# MSS_CPSW register map
Vendor: Texas Instruments
Registers are 32-bit, read-write, no defined reset value unless marked. A register's access mark holds for its fields unless they carry their own. Offsets are as the file gives them; [hi:lo] are bit positions; {n}, {i} and the like mark numbered series.

## MSS_CPSW (part 3 of 3)
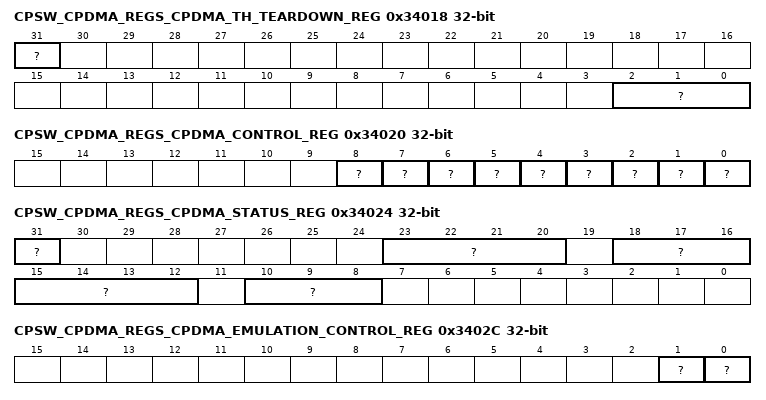
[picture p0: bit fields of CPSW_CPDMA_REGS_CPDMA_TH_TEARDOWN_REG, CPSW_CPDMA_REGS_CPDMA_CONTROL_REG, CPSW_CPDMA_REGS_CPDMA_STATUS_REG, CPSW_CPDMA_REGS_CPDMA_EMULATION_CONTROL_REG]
0x34018 CPSW_CPDMA_REGS_CPDMA_TH_TEARDOWN_REG — CPDMA THost Teardown Register
  [31] ? — CPDMA THost Teardown Ready
  [2:0] ? — CPDMA THost Teardown Channel
0x3401C CPSW_CPDMA_REGS_CPDMA_SOFT_RESET_REG — CPDMA Soft Reset Register
  [0] ? — CPDMA and CPSW Soft Reset Enable
0x34020 CPSW_CPDMA_REGS_CPDMA_CONTROL_REG — CPDMA Control Register
  [8] ? — CPDMA FHost Ownership Write Bit Value
  [7] ? — CPDMA Channel Thread Override Enable
  [6] ? — CPDMA THost TimeStamp Encapsulated
  [5] ? — CPDMA THost VLAN Encapsulated
  [4] ? — CPDMA THost Copy Error Frames
  [3] ? — CPDMA Command Idle
  [2] ? — CPDMA THost Offset/Length Word Write Block
  [1] ? — CPDMA THost Ownership Write Bit Value
  [0] ? — CPDMA FHost Queue Priority Type
0x34024 CPSW_CPDMA_REGS_CPDMA_STATUS_REG ro — CPDMA Status Register
  [31] ? — CPDMA FHost Host Error Code
  [23:20] ? — CPDMA FHost Host Error Code
  [18:16] ? — CPDMA FHost Error Channel Number
  [15:12] ? — CPDMA THost Host Error Code
  [10:8] ? — CPDMA THost Error Channel Number
0x34028 CPSW_CPDMA_REGS_CPDMA_TH_BUFFER_OFFSET_REG — CPDMA THost Buffer Offset Register
  [11:0] ?
0x3402C CPSW_CPDMA_REGS_CPDMA_EMULATION_CONTROL_REG — CPDMA THost Buffer Offset Register
  [1] ? — CPDMA THost Buffer Offset Register
  [0] ? — CPDMA THost Buffer Offset Register
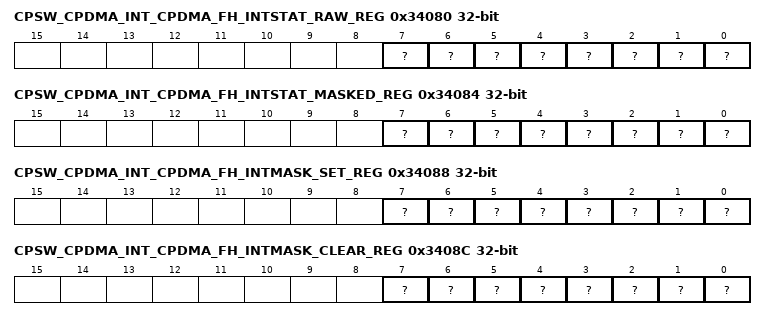
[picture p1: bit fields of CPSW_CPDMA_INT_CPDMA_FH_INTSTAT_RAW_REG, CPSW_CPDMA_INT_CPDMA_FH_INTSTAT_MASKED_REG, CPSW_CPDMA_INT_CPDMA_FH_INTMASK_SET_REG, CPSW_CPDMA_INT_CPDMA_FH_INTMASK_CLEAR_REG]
0x34080 CPSW_CPDMA_INT_CPDMA_FH_INTSTAT_RAW_REG ro — CPDMA FHost Interrupt Status RAW
  [7] ? — CPDMA FHost Channel 7 Interrupt Pending RAW
  [6] ? — CPDMA FHost Channel 6 Interrupt Pending RAW
  [5] ? — CPDMA FHost Channel 5 Interrupt Pending RAW
  [4] ? — CPDMA FHost Channel 4 Interrupt Pending RAW
  [3] ? — CPDMA FHost Channel 3 Interrupt Pending RAW
  [2] ? — CPDMA FHost Channel 2 Interrupt Pending RAW
  [1] ? — CPDMA FHost Channel 1 Interrupt Pending RAW
  [0] ? — CPDMA FHost Channel 0 Interrupt Pending RAW
0x34084 CPSW_CPDMA_INT_CPDMA_FH_INTSTAT_MASKED_REG ro — CPDMA FHost Interrupt Status MASKED
  [7] ? — CPDMA FHost Channel 7 Interrupt Pending MASKED
  [6] ? — CPDMA FHost Channel 6 Interrupt Pending MASKED
  [5] ? — CPDMA FHost Channel 5 Interrupt Pending MASKED
  [4] ? — CPDMA FHost Channel 4 Interrupt Pending MASKED
  [3] ? — CPDMA FHost Channel 3 Interrupt Pending MASKED
  [2] ? — CPDMA FHost Channel 2 Interrupt Pending MASKED
  [1] ? — CPDMA FHost Channel 1 Interrupt Pending MASKED
  [0] ? — CPDMA FHost Channel 0 Interrupt Pending MASKED
0x34088 CPSW_CPDMA_INT_CPDMA_FH_INTMASK_SET_REG — CPDMA FHost Interrupt Masked SET
  [7] ? — CPDMA FHost Channel 7 Interrupt Pending MASKED Set
  [6] ? — CPDMA FHost Channel 6 Interrupt Pending MASKED Set
  [5] ? — CPDMA FHost Channel 5 Interrupt Pending MASKED Set
  [4] ? — CPDMA FHost Channel 4 Interrupt Pending MASKED Set
  [3] ? — CPDMA FHost Channel 3 Interrupt Pending MASKED Set
  [2] ? — CPDMA FHost Channel 2 Interrupt Pending MASKED Set
  [1] ? — CPDMA FHost Channel 1 Interrupt Pending MASKED Set
  [0] ? — CPDMA FHost Channel 0 Interrupt Pending MASKED Set
0x3408C CPSW_CPDMA_INT_CPDMA_FH_INTMASK_CLEAR_REG — CPDMA FHost Interrupt Masked CLR
  [7] ? — CPDMA FHost Channel 7 Interrupt Pending MASKED Clr
  [6] ? — CPDMA FHost Channel 6 Interrupt Pending MASKED Clr
  [5] ? — CPDMA FHost Channel 5 Interrupt Pending MASKED Clr
  [4] ? — CPDMA FHost Channel 4 Interrupt Pending MASKED Clr
  [3] ? — CPDMA FHost Channel 3 Interrupt Pending MASKED Clr
  [2] ? — CPDMA FHost Channel 2 Interrupt Pending MASKED Clr
  [1] ? — CPDMA FHost Channel 1 Interrupt Pending MASKED Clr
  [0] ? — CPDMA FHost Channel 0 Interrupt Pending MASKED Clr
0x34090 CPSW_CPDMA_INT_CPDMA_IN_VECTOR_REG ro — CPDMA DMA IN Vector
  [31:0] ?
0x34094 CPSW_CPDMA_INT_CPDMA_EOI_VECTOR_REG — CPDMA DMA EOI Vector
  [4:0] ?
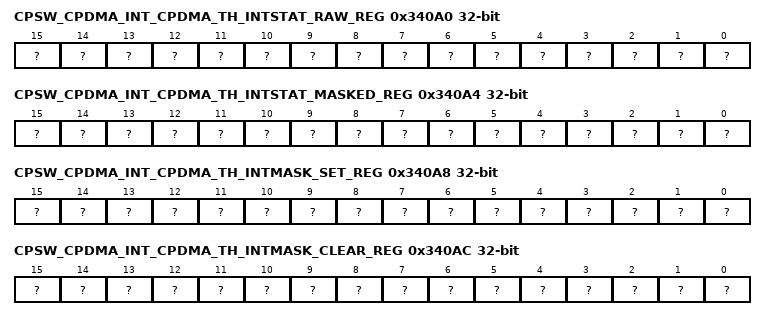
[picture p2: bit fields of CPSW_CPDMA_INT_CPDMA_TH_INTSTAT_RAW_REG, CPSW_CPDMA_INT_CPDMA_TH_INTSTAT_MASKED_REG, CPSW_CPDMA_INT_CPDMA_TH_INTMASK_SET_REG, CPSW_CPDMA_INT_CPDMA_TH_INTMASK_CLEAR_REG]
0x340A0 CPSW_CPDMA_INT_CPDMA_TH_INTSTAT_RAW_REG ro — CPDMA Receive Interrupt Status RAW
  [15] ? — CPDMA Receive Channel 7 Threshold Interrupt Pending RAW
  [14] ? — CPDMA Receive Channel 6 Threshold Interrupt Pending RAW
  [13] ? — CPDMA Receive Channel 5 Threshold Interrupt Pending RAW
  [12] ? — CPDMA Receive Channel 4 Threshold Interrupt Pending RAW
  [11] ? — CPDMA Receive Channel 3 Threshold Interrupt Pending RAW
  [10] ? — CPDMA Receive Channel 2 Threshold Interrupt Pending RAW
  [9] ? — CPDMA Receive Channel 1 Threshold Interrupt Pending RAW
  [8] ? — CPDMA Receive Channel 0 Threshold Interrupt Pending RAW
  [7] ? — CPDMA Receive Channel 7 Interrupt Pending RAW
  [6] ? — CPDMA Receive Channel 6 Interrupt Pending RAW
  [5] ? — CPDMA Receive Channel 5 Interrupt Pending RAW
  [4] ? — CPDMA Receive Channel 4 Interrupt Pending RAW
  [3] ? — CPDMA Receive Channel 3 Interrupt Pending RAW
  [2] ? — CPDMA Receive Channel 2 Interrupt Pending RAW
  [1] ? — CPDMA Receive Channel 1 Interrupt Pending RAW
  [0] ? — CPDMA Receive Channel 0 Interrupt Pending RAW
0x340A4 CPSW_CPDMA_INT_CPDMA_TH_INTSTAT_MASKED_REG ro — CPDMA Receive Interrupt Status MASKED
  [15] ? — CPDMA Receive Channel 7 Threshold Interrupt Pending MASKED
  [14] ? — CPDMA Receive Channel 6 Threshold Interrupt Pending MASKED
  [13] ? — CPDMA Receive Channel 5 Threshold Interrupt Pending MASKED
  [12] ? — CPDMA Receive Channel 4 Threshold Interrupt Pending MASKED
  [11] ? — CPDMA Receive Channel 3 Threshold Interrupt Pending MASKED
  [10] ? — CPDMA Receive Channel 2 Threshold Interrupt Pending MASKED
  [9] ? — CPDMA Receive Channel 1 Threshold Interrupt Pending MASKED
  [8] ? — CPDMA Receive Channel 0 Threshold Interrupt Pending MASKED
  [7] ? — CPDMA Receive Channel 7 Interrupt Pending MASKED
  [6] ? — CPDMA Receive Channel 6 Interrupt Pending MASKED
  [5] ? — CPDMA Receive Channel 5 Interrupt Pending MASKED
  [4] ? — CPDMA Receive Channel 4 Interrupt Pending MASKED
  [3] ? — CPDMA Receive Channel 3 Interrupt Pending MASKED
  [2] ? — CPDMA Receive Channel 2 Interrupt Pending MASKED
  [1] ? — CPDMA Receive Channel 1 Interrupt Pending MASKED
  [0] ? — CPDMA Receive Channel 0 Interrupt Pending MASKED
0x340A8 CPSW_CPDMA_INT_CPDMA_TH_INTMASK_SET_REG — CPDMA THost Interrupt Masked SET
  [15] ? — CPDMA THost Channel 7 Threshold Interrupt Pending SET
  [14] ? — CPDMA THost Channel 6 Threshold Interrupt Pending SET
  [13] ? — CPDMA THost Channel 5 Threshold Interrupt Pending SET
  [12] ? — CPDMA THost Channel 4 Threshold Interrupt Pending SET
  [11] ? — CPDMA THost Channel 3 Threshold Interrupt Pending SET
  [10] ? — CPDMA THost Channel 2 Threshold Interrupt Pending SET
  [9] ? — CPDMA THost Channel 1 Threshold Interrupt Pending SET
  [8] ? — CPDMA THost Channel 0 Threshold Interrupt Pending SET
  [7] ? — CPDMA THost Channel 7 Interrupt Pending SET
  [6] ? — CPDMA THost Channel 6 Interrupt Pending SET
  [5] ? — CPDMA THost Channel 5 Interrupt Pending SET
  [4] ? — CPDMA THost Channel 4 Interrupt Pending SET
  [3] ? — CPDMA THost Channel 3 Interrupt Pending SET
  [2] ? — CPDMA THost Channel 2 Interrupt Pending SET
  [1] ? — CPDMA THost Channel 1 Interrupt Pending SET
  [0] ? — CPDMA THost Channel 0 Interrupt Pending SET
0x340AC CPSW_CPDMA_INT_CPDMA_TH_INTMASK_CLEAR_REG — CPDMA THost Interrupt Masked CLR
  [15] ? — CPDMA THost Channel 7 Threshold Interrupt Pending CLR
  [14] ? — CPDMA THost Channel 6 Threshold Interrupt Pending CLR
  [13] ? — CPDMA THost Channel 5 Threshold Interrupt Pending CLR
  [12] ? — CPDMA THost Channel 4 Threshold Interrupt Pending CLR
  [11] ? — CPDMA THost Channel 3 Threshold Interrupt Pending CLR
  [10] ? — CPDMA THost Channel 2 Threshold Interrupt Pending CLR
  [9] ? — CPDMA THost Channel 1 Threshold Interrupt Pending CLR
  [8] ? — CPDMA THost Channel 0 Threshold Interrupt Pending CLR
  [7] ? — CPDMA THost Channel 7 Interrupt Pending CLR
  [6] ? — CPDMA THost Channel 6 Interrupt Pending CLR
  [5] ? — CPDMA THost Channel 5 Interrupt Pending CLR
  [4] ? — CPDMA THost Channel 4 Interrupt Pending CLR
  [3] ? — CPDMA THost Channel 3 Interrupt Pending CLR
  [2] ? — CPDMA THost Channel 2 Interrupt Pending CLR
  [1] ? — CPDMA THost Channel 1 Interrupt Pending CLR
  [0] ? — CPDMA THost Channel 0 Interrupt Pending CLR
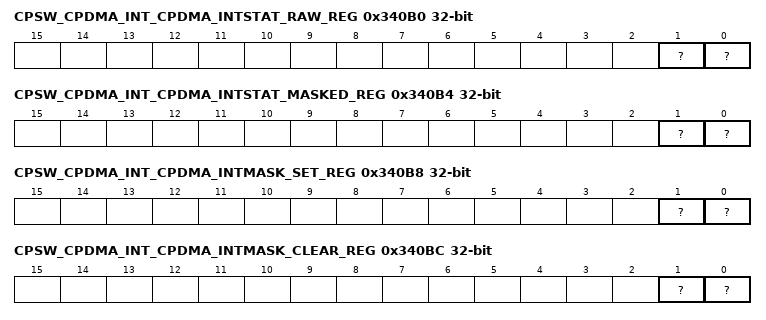
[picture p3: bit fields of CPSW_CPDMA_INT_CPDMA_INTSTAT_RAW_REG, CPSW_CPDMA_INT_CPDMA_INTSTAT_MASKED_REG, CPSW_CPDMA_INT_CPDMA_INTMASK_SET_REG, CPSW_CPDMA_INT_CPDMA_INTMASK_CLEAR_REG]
0x340B0 CPSW_CPDMA_INT_CPDMA_INTSTAT_RAW_REG ro — CPDMA DMA Interrupt Status RAW
  [1] ? — CPDMA HOST Interrupt Pending RAW
  [0] ? — CPDMA Statistics Interrupt Pending RAW
0x340B4 CPSW_CPDMA_INT_CPDMA_INTSTAT_MASKED_REG ro — CPDMA DMA Interrupt Status MASKED
  [1] ? — CPDMA HOST Interrupt Pending MASKED
  [0] ? — CPDMA Statistics Interrupt Pending MASKED
0x340B8 CPSW_CPDMA_INT_CPDMA_INTMASK_SET_REG — CPDMA DMA Interrupt Status SET
  [1] ? — CPDMA HOST Interrupt Masked SET
  [0] ? — CPDMA Statistics Interrupt Masked SET
0x340BC CPSW_CPDMA_INT_CPDMA_INTMASK_CLEAR_REG — CPDMA DMA Interrupt Status CLR
  [1] ? — CPDMA HOST Interrupt Masked CLR
  [0] ? — CPDMA Statistics Interrupt Masked CLR
{0x340C0+4i} CPSW_CPDMA_INT_CPDMA_TH{i}_PENDTHRESH_REG (i=0..7) — CPDMA THost Threshold Pending Register
  [7:0] ?
{0x340E0+4i} CPSW_CPDMA_INT_CPDMA_TH{i}_FREEBUFFER_REG (i=0..7) — CPDMA THost Free Buffer Count Register
  [14:0] ?
{0x34200+4i} CPSW_CPDMA_SRAM_CPDMA_FH{i}_HDP_REG (i=0..7) — CPDMA FHost Channel {i} Head Descriptor Pointer
  [31:0] ?
{0x34220+4i} CPSW_CPDMA_SRAM_CPDMA_TH{i}_HDP_REG (i=0..7) — CPDMA THost Channel {i} Head Descriptor Pointer
  [31:0] ?
{0x34240+4i} CPSW_CPDMA_SRAM_CPDMA_FH{i}_CP_REG (i=0..7) — CPDMA FHost Channel {i} Completion Pointer
  [31:0] ?
{0x34260+4i} CPSW_CPDMA_SRAM_CPDMA_TH{i}_CP_REG (i=0..7) — CPDMA THost Channel {i} Completion Pointer
  [31:0] ?
{0x34300+4i} CPSW_CPDMA_SRAM_TEST_CPDMA_FH{i}_HDP_REG (i=0..7) — Test CPDMA FHost Channel {i} Head Descriptor Pointer
  [31:0] ?
{0x34320+4i} CPSW_CPDMA_SRAM_TEST_CPDMA_TH{i}_HDP_REG (i=0..7) — Test CPDMA THost Channel {i} Head Descriptor Pointer
  [31:0] ?
{0x34340+4i} CPSW_CPDMA_SRAM_TEST_CPDMA_FH{i}_CP_REG (i=0..7) — Test CPDMA FHost Channel {i} Completion Pointer
  [31:0] ?
{0x34360+4i} CPSW_CPDMA_SRAM_TEST_CPDMA_TH{i}_CP_REG (i=0..7) — Test CPDMA THost Channel {i} Completion Pointer
  [31:0] ?
0x3A000 CPSW_NC_STAT_0_RXGOODFRAMES — Total number of good frames received
  [31:0] ?
0x3A004 CPSW_NC_STAT_0_RXBROADCASTFRAMES — Total number of good broadcast frames received
  [31:0] ?
0x3A008 CPSW_NC_STAT_0_RXMULTICASTFRAMES — Total number of good multicast frames received
  [31:0] ?
0x3A010 CPSW_NC_STAT_0_RXCRCERRORS — Total number of CRC errors frames received
  [31:0] ?
0x3A018 CPSW_NC_STAT_0_RXOVERSIZEDFRAMES — Total number of oversized frames received
  [31:0] ?
0x3A020 CPSW_NC_STAT_0_RXUNDERSIZEDFRAMES — Total number of undersized frames received
  [31:0] ?
0x3A024 CPSW_NC_STAT_0_RXFRAGMENTS — Total number of fragmented frames received
  [31:0] ?
0x3A028 CPSW_NC_STAT_0_ALE_DROP — Total number of frames dropped by the ALE
  [31:0] ?
0x3A02C CPSW_NC_STAT_0_ALE_OVERRUN_DROP — Total number of overrun frames dropped by the ALE
  [31:0] ?
0x3A030 CPSW_NC_STAT_0_RXOCTETS — Total number of received bytes in good frames
  [31:0] ?
0x3A034 CPSW_NC_STAT_0_TXGOODFRAMES — Total number of good frames transmitted
  [31:0] ?
0x3A038 CPSW_NC_STAT_0_TXBROADCASTFRAMES — Total number of good broadcast frames transmitted
  [31:0] ?
0x3A03C CPSW_NC_STAT_0_TXMULTICASTFRAMES — Total number of good multicast frames transmitted
  [31:0] ?
0x3A04C CPSW_NC_STAT_0_TXSINGLECOLLFRAMES — Total number of transmitted frames experiencing a single collision
  [31:0] ?
0x3A050 CPSW_NC_STAT_0_TXMULTCOLLFRAMES — Total number of transmitted frames experiencing multiple collisions
  [31:0] ?
0x3A064 CPSW_NC_STAT_0_TXOCTETS — Total number of bytes in all good frames transmitted
  [31:0] ?
0x3A068 CPSW_NC_STAT_0_OCTETFRAMES64 — Total number of 64-byte frames received and transmitted
  [31:0] ?
0x3A06C CPSW_NC_STAT_0_OCTETFRAMES65T127 — Total number of frames of size 65 to 127 bytes received and transmitted
  [31:0] ?
0x3A070 CPSW_NC_STAT_0_OCTETFRAMES128T255 — Total number of frames of size 128 to 255 bytes received and transmitted
  [31:0] ?
0x3A074 CPSW_NC_STAT_0_OCTETFRAMES256T511 — Total number of frames of size 256 to 511 bytes received and transmitted
  [31:0] ?
0x3A078 CPSW_NC_STAT_0_OCTETFRAMES512T1023 — Total number of frames of size 512 to 1023 bytes received and transmitted
  [31:0] ?
0x3A07C CPSW_NC_STAT_0_OCTETFRAMES1024TUP — Total number of frames of size 1024 to rx_maxlen bytes received and 1024 bytes or greater transmitted
  [31:0] ?
0x3A080 CPSW_NC_STAT_0_NETOCTETS — Total number of bytes received and transmitted
  [31:0] ?
0x3A084 CPSW_NC_STAT_0_RX_BOTTOM_OF_FIFO_DROP — Receive Bottom of FIFO Drop
  [31:0] ?
0x3A088 CPSW_NC_STAT_0_PORTMASK_DROP — Total number of dropped frames received due to portmask
  [31:0] ?
0x3A08C CPSW_NC_STAT_0_RX_TOP_OF_FIFO_DROP — Receive Top of FIFO Drop
  [31:0] ?
0x3A090 CPSW_NC_STAT_0_ALE_RATE_LIMIT_DROP — Total number of dropped frames due to ALE Rate Limiting
  [31:0] ?
0x3A094 CPSW_NC_STAT_0_ALE_VID_INGRESS_DROP — Total number of dropped frames due to ALE VID Ingress
  [31:0] ?
0x3A098 CPSW_NC_STAT_0_ALE_DA_EQ_SA_DROP — Total number of dropped frames due to DA=SA
  [31:0] ?
0x3A09C CPSW_NC_STAT_0_ALE_BLOCK_DROP — Total number of dropped frames due to ALE Block Mode
  [31:0] ?
0x3A0A0 CPSW_NC_STAT_0_ALE_SECURE_DROP — Total number of dropped frames due to ALE Secure Mode
  [31:0] ?
0x3A0A4 CPSW_NC_STAT_0_ALE_AUTH_DROP — Total number of dropped frames due to ALE Authentication
  [31:0] ?
0x3A0A8 CPSW_NC_STAT_0_ALE_UNKN_UNI — ALE Receive Unknown Unicast
  [31:0] ?
0x3A0AC CPSW_NC_STAT_0_ALE_UNKN_UNI_BCNT — ALE Receive Unknown Unicast Bytecount
  [31:0] ?
0x3A0B0 CPSW_NC_STAT_0_ALE_UNKN_MLT — ALE Receive Unknown Multicast
  [31:0] ?
0x3A0B4 CPSW_NC_STAT_0_ALE_UNKN_MLT_BCNT — ALE Receive Unknown Multicast Bytecount
  [31:0] ?
0x3A0B8 CPSW_NC_STAT_0_ALE_UNKN_BRD — ALE Receive Unknown Broadcast
  [31:0] ?
0x3A0BC CPSW_NC_STAT_0_ALE_UNKN_BRD_BCNT — ALE Receive Unknown Broadcast Bytecount
  [31:0] ?
0x3A0C0 CPSW_NC_STAT_0_ALE_POL_MATCH — ALE Policer Matched
  [31:0] ?
0x3A0C4 CPSW_NC_STAT_0_ALE_POL_MATCH_RED — ALE Policer Matched and Condition Red
  [31:0] ?
0x3A0C8 CPSW_NC_STAT_0_ALE_POL_MATCH_YELLOW — ALE Policer Matched and Condition Yellow
  [31:0] ?
0x3A0CC CPSW_NC_STAT_0_ALE_MULT_SA_DROP — ALE Multicast Source Address Drop
  [31:0] ? — ALE Multicast Source Address drop
0x3A0D0 CPSW_NC_STAT_0_ALE_DUAL_VLAN_DROP — ALE Dual VLAN Drop
  [31:0] ? — ALE Dual VLAN drop
0x3A0D4 CPSW_NC_STAT_0_ALE_LEN_ERROR_DROP — ALE Length Error Drop
  [31:0] ? — ALE Length Error drop
0x3A0D8 CPSW_NC_STAT_0_ALE_IP_NEXT_HDR_DROP — ALE IP Next Header Drop
  [31:0] ? — ALE Next Header drop
0x3A0DC CPSW_NC_STAT_0_ALE_IPV4_FRAG_DROP — ALE IPV4 Frag Drop
  [31:0] ? — ALE IPV4 Fragment drop
0x3A17C CPSW_NC_STAT_0_TX_MEMORY_PROTECT_ERROR — Transmit Memory Protect CRC Error
  [7:0] ?
0x3A200 CPSW_NC_STAT_1_RXGOODFRAMES — Total number of good frames received
  [31:0] ?
0x3A204 CPSW_NC_STAT_1_RXBROADCASTFRAMES — Total number of good broadcast frames received
  [31:0] ?
0x3A208 CPSW_NC_STAT_1_RXMULTICASTFRAMES — Total number of good multicast frames received
  [31:0] ?
0x3A20C CPSW_NC_STAT_1_RXPAUSEFRAMES — Total number of pause frames received
  [31:0] ?
0x3A210 CPSW_NC_STAT_1_RXCRCERRORS — Total number of CRC errors frames received
  [31:0] ?
0x3A214 CPSW_NC_STAT_1_RXALIGNCODEERRORS — Total number of alignment/code errors received
  [31:0] ?
0x3A218 CPSW_NC_STAT_1_RXOVERSIZEDFRAMES — Total number of oversized frames received
  [31:0] ?
0x3A21C CPSW_NC_STAT_1_RXJABBERFRAMES — Total number of jabber frames received
  [31:0] ?
0x3A220 CPSW_NC_STAT_1_RXUNDERSIZEDFRAMES — Total number of undersized frames received
  [31:0] ?
0x3A224 CPSW_NC_STAT_1_RXFRAGMENTS — Total number of fragmented frames received
  [31:0] ?
0x3A228 CPSW_NC_STAT_1_ALE_DROP — Total number of frames dropped by the ALE
  [31:0] ?
0x3A22C CPSW_NC_STAT_1_ALE_OVERRUN_DROP — Total number of overrun frames dropped by the ALE
  [31:0] ?
0x3A230 CPSW_NC_STAT_1_RXOCTETS — Total number of received bytes in good frames
  [31:0] ?
0x3A234 CPSW_NC_STAT_1_TXGOODFRAMES — Total number of good frames transmitted
  [31:0] ?
0x3A238 CPSW_NC_STAT_1_TXBROADCASTFRAMES — Total number of good broadcast frames transmitted
  [31:0] ?
0x3A23C CPSW_NC_STAT_1_TXMULTICASTFRAMES — Total number of good multicast frames transmitted
  [31:0] ?
0x3A240 CPSW_NC_STAT_1_TXPAUSEFRAMES — Total number of pause frames transmitted
  [31:0] ?
0x3A244 CPSW_NC_STAT_1_TXDEFERREDFRAMES — Total number of deferred frames transmitted
  [31:0] ?
0x3A248 CPSW_NC_STAT_1_TXCOLLISIONFRAMES — Total number of transmitted frames experiencing a collision
  [31:0] ?
0x3A24C CPSW_NC_STAT_1_TXSINGLECOLLFRAMES — Total number of transmitted frames experiencing a single collision
  [31:0] ?
0x3A250 CPSW_NC_STAT_1_TXMULTCOLLFRAMES — Total number of transmitted frames experiencing multiple collisions
  [31:0] ?
0x3A254 CPSW_NC_STAT_1_TXEXCESSIVECOLLISIONS — Total number of transmitted frames abandoned due to excessive collisions
  [31:0] ?
0x3A258 CPSW_NC_STAT_1_TXLATECOLLISIONS — Total number of transmitted frames abandoned due to a late collision
  [31:0] ?
0x3A25C CPSW_NC_STAT_1_RXIPGERROR — Total number of receive inter-packet gap errors (10G only)
  [31:0] ?
0x3A260 CPSW_NC_STAT_1_TXCARRIERSENSEERRORS — Total number of transmitted frames that experienced a carrier loss
  [31:0] ?
0x3A264 CPSW_NC_STAT_1_TXOCTETS — Total number of bytes in all good frames transmitted
  [31:0] ?
0x3A268 CPSW_NC_STAT_1_OCTETFRAMES64 — Total number of 64-byte frames received and transmitted
  [31:0] ?
0x3A26C CPSW_NC_STAT_1_OCTETFRAMES65T127 — Total number of frames of size 65 to 127 bytes received and transmitted
  [31:0] ?
0x3A270 CPSW_NC_STAT_1_OCTETFRAMES128T255 — Total number of frames of size 128 to 255 bytes received and transmitted
  [31:0] ?
0x3A274 CPSW_NC_STAT_1_OCTETFRAMES256T511 — Total number of frames of size 256 to 511 bytes received and transmitted
  [31:0] ?
0x3A278 CPSW_NC_STAT_1_OCTETFRAMES512T1023 — Total number of frames of size 512 to 1023 bytes received and transmitted
  [31:0] ?
0x3A27C CPSW_NC_STAT_1_OCTETFRAMES1024TUP — Total number of frames of size 1024 to rx_maxlen bytes received and 1024 bytes or greater transmitted
  [31:0] ?
0x3A280 CPSW_NC_STAT_1_NETOCTETS — Total number of bytes received and transmitted
  [31:0] ?
0x3A284 CPSW_NC_STAT_1_RX_BOTTOM_OF_FIFO_DROP — Receive Bottom of FIFO Drop
  [31:0] ?
0x3A288 CPSW_NC_STAT_1_PORTMASK_DROP — Total number of dropped frames received due to portmask
  [31:0] ?
0x3A28C CPSW_NC_STAT_1_RX_TOP_OF_FIFO_DROP — Receive Top of FIFO Drop
  [31:0] ?
0x3A290 CPSW_NC_STAT_1_ALE_RATE_LIMIT_DROP — Total number of dropped frames due to ALE Rate Limiting
  [31:0] ?
0x3A294 CPSW_NC_STAT_1_ALE_VID_INGRESS_DROP — Total number of dropped frames due to ALE VID Ingress
  [31:0] ?
0x3A298 CPSW_NC_STAT_1_ALE_DA_EQ_SA_DROP — Total number of dropped frames due to DA=SA
  [31:0] ?
0x3A29C CPSW_NC_STAT_1_ALE_BLOCK_DROP — Total number of dropped frames due to ALE Block Mode
  [31:0] ?
0x3A2A0 CPSW_NC_STAT_1_ALE_SECURE_DROP — Total number of dropped frames due to ALE Secure Mode
  [31:0] ?
0x3A2A4 CPSW_NC_STAT_1_ALE_AUTH_DROP — Total number of dropped frames due to ALE Authentication
  [31:0] ?
0x3A2A8 CPSW_NC_STAT_1_ALE_UNKN_UNI — ALE Receive Unknown Unicast
  [31:0] ?
0x3A2AC CPSW_NC_STAT_1_ALE_UNKN_UNI_BCNT — ALE Receive Unknown Unicast Bytecount
  [31:0] ?
0x3A2B0 CPSW_NC_STAT_1_ALE_UNKN_MLT — ALE Receive Unknown Multicast
  [31:0] ?
0x3A2B4 CPSW_NC_STAT_1_ALE_UNKN_MLT_BCNT — ALE Receive Unknown Multicast Bytecount
  [31:0] ?
0x3A2B8 CPSW_NC_STAT_1_ALE_UNKN_BRD — ALE Receive Unknown Broadcast
  [31:0] ?
0x3A2BC CPSW_NC_STAT_1_ALE_UNKN_BRD_BCNT — ALE Receive Unknown Broadcast Bytecount
  [31:0] ?
0x3A2C0 CPSW_NC_STAT_1_ALE_POL_MATCH — ALE Policer Matched
  [31:0] ?
0x3A2C4 CPSW_NC_STAT_1_ALE_POL_MATCH_RED — ALE Policer Matched and Condition Red
  [31:0] ?
0x3A2C8 CPSW_NC_STAT_1_ALE_POL_MATCH_YELLOW — ALE Policer Matched and Condition Yellow
  [31:0] ?
0x3A2CC CPSW_NC_STAT_1_ALE_MULT_SA_DROP — ALE Multicast Source Address Drop
  [31:0] ? — ALE Multicast Source Address drop
0x3A2D0 CPSW_NC_STAT_1_ALE_DUAL_VLAN_DROP — ALE Dual VLAN Drop
  [31:0] ? — ALE Dual VLAN drop
0x3A2D4 CPSW_NC_STAT_1_ALE_LEN_ERROR_DROP — ALE Length Error Drop
  [31:0] ? — ALE Length Error drop
0x3A2D8 CPSW_NC_STAT_1_ALE_IP_NEXT_HDR_DROP — ALE IP Next Header Drop
  [31:0] ? — ALE Next Header drop
0x3A2DC CPSW_NC_STAT_1_ALE_IPV4_FRAG_DROP — ALE IPV4 Frag Drop
  [31:0] ? — ALE IPV4 Fragment drop
0x3A37C CPSW_NC_STAT_1_TX_MEMORY_PROTECT_ERROR — Transmit Memory Protect CRC Error
  [7:0] ?
{0x3A380+4i} CPSW_NC_STAT_1_ENET_PN_TX_PRI_REG_{i} (i=0..7) — ENET Port n PRIORITY N Packet Count
  [31:0] ? — ENET TX Priority Packet Count
{0x3A3A0+4i} CPSW_NC_STAT_1_ENET_PN_TX_PRI_BCNT_REG_{i} (i=0..7) — ENET Port n PRIORITY N Packet Byte Count
  [31:0] ?
{0x3A3C0+4i} CPSW_NC_STAT_1_ENET_PN_TX_PRI_DROP_REG_{i} (i=0..7) — ENET Port n PRIORITY N Packet Drop Count
  [31:0] ?
{0x3A3E0+4i} CPSW_NC_STAT_1_ENET_PN_TX_PRI_DROP_BCNT_REG_{i} (i=0..7) — ENET Port n PRIORITY N Packet Drop Byte Count
  [31:0] ?
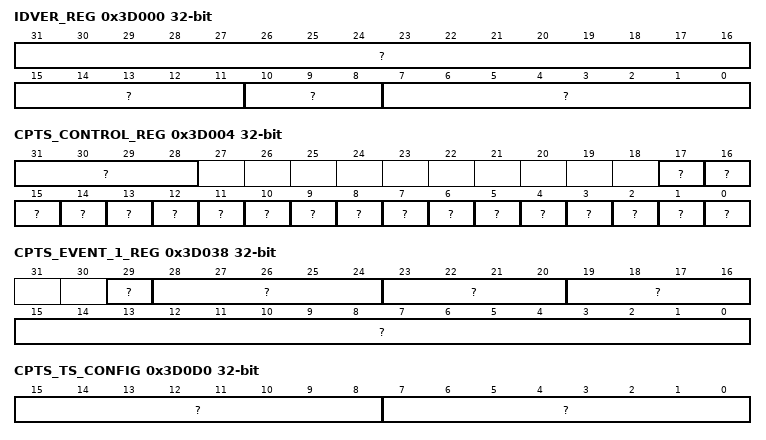
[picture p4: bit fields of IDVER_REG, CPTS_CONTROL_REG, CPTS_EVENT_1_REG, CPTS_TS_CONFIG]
0x3D000 IDVER_REG ro — Identification and Version Register
  [31:16] ? — Identification value
  [15:11] ? — RTL version value
  [10:8] ? — Major version value
  [7:0] ? — Minor version value
0x3D004 CPTS_CONTROL_REG — Time Sync Control Register
  [31:28] ? — TS_SYNC output timestamp counter bit select
  [17] ? — Enable for GENF clear when length is zero
  [16] ? — Receive Produces no Events
  [15] ? — Hardware push 8 enable
  [14] ? — Hardware push 7 enable
  [13] ? — Hardware push 6 enable
  [12] ? — Hardware push 5 enable
  [11] ? — Hardware push 4 enable
  [10] ? — Hardware push 3 enable
  [9] ? — Hardware push 2 enable
  [8] ? — Hardware push 1 enable
  [7] ? — Timestamp PPM Direction
  [6] ? — Timestamp Compare Toggle mode: 0=TS_COMP is in non-toggle mode, 1=TS_COMP is in toggle mode
  [5] ? — Timestamp mode
  [4] ? — Sequence Enable
  [3] ? — Host Receive Timestamp Enable
  [2] ? — TS_COMP polarity
  [1] ? — Interrupt test
  [0] ? — Time sync enable
0x3D008 CPTS_RFTCLK_SEL_REG — RFTCLK Select Register
  [4:0] ? — Reference clock select
0x3D00C CPTS_TS_PUSH_REG wo — Time Stamp Event Push Register
  [0] ? — Time stamp event push
0x3D010 TS_LOAD_VAL_REG — Time Stamp Load Low Value Register
  [31:0] ? — Time stamp load low value
0x3D014 CPTS_TS_LOAD_EN_REG wo — Time Stamp Load Enable Register
  [0] ? — Time stamp load enable
0x3D018 TS_COMP_VAL_REG — Time Stamp Comparison Low Value Register
  [31:0] ? — Time stamp comparison low value
0x3D01C CPTS_TS_COMP_LEN_REG — Time Stamp Comparison Length Register
  [31:0] ? — Time stamp comparison length
0x3D020 CPTS_INTSTAT_RAW_REG — Interrupt Status Register Raw
  [0] ? — TS_PEND_RAW int read (before enable)
0x3D024 CPTS_INTSTAT_MASKED_REG ro — Interrupt Status Register Masked
  [0] ? — TS_PEND masked interrupt read (after enable)
0x3D028 CPTS_INT_ENABLE_REG — Interrupt Enable Register
  [0] ? — TS_PEND masked interrupt enable
0x3D02C CPTS_TS_COMP_NUDGE_REG — Time Stamp Comparison Nudge Register
  [7:0] ? — This 2s complement number is added to the ts_comp_length value to increase or decrease the TS_COMP length by the nudge amount
0x3D030 CPTS_EVENT_POP_REG wo — Event Pop Register
  [0] ? — Event pop
0x3D034 CPTS_EVENT_0_REG ro — Event 0 Register
  [31:0] ? — Time Stamp
0x3D038 CPTS_EVENT_1_REG ro — Event 1 Register
  [29] ? — Prempt QUEUE
  [28:24] ? — Port number
  [23:20] ? — Event type
  [19:16] ? — Message type
  [15:0] ? — Sequence ID
0x3D03C CPTS_EVENT_2_REG ro — Event 2 Register
  [7:0] ? — Domain
0x3D040 CPTS_EVENT_3_REG ro — Event 3 Register
  [31:0] ? — Time Stamp
0x3D044 CPTS_TS_LOAD_HIGH_VAL_REG — Time Stamp Load High Value Register
  [31:0] ? — Time stamp load high value
0x3D048 CPTS_TS_COMP_HIGH_VAL_REG — Time Stamp Comparison High Value Register
  [31:0] ? — Time stamp comparison high value
0x3D04C CPTS_TS_ADD_VAL_REG — TS Add Value Register
  [2:0] ? — Add Value
0x3D050 CPTS_TS_PPM_LOW_VAL_REG — Time Stamp PPM Low Value Register
  [31:0] ? — Time stamp PPM Low value
0x3D054 CPTS_TS_PPM_HIGH_VAL_REG — Time Stamp PPM High Value Register
  [9:0] ? — Time stamp PPM High value
0x3D058 CPTS_TS_NUDGE_VAL_REG — Time Stamp Nudge Value Register
  [7:0] ? — Time stamp Nudge value
0x3D0D0 CPTS_TS_CONFIG ro — Time Stamp Configuration Read
  [15:8] ? — The Event FIFO Depth
  [7:0] ? — The number of CPTS GENF outputs
{0x3D0E0+0x20*i} TS_GENF{i}_COMP_LOW_REG (i=0..2) — Time Stamp Generate Function Comparison Low Value
  [31:0] ?
{0x3D0E4+0x20*i} TS_GENF{i}_COMP_HIGH_REG (i=0..2) — Time Stamp Generate Function Comparison high Value
  [31:0] ? — Time Stamp Generate Function Comparison High Value
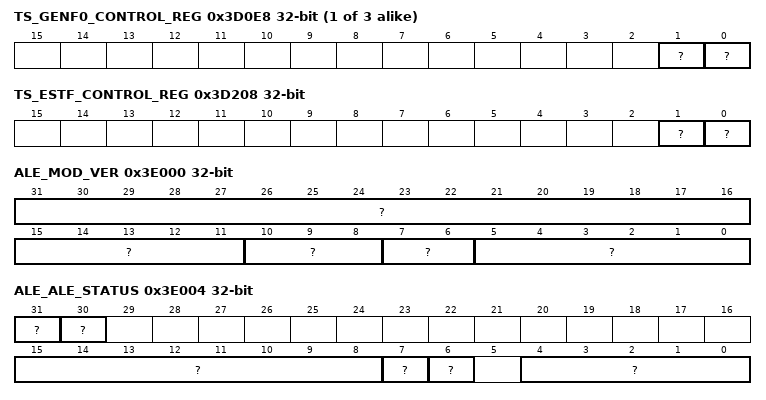
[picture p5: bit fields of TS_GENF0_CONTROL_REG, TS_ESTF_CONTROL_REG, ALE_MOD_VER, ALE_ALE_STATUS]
{0x3D0E8+0x20*i} TS_GENF{i}_CONTROL_REG (i=0..2) — Time Stamp Generate Function Control
  [1] ? — Time Stamp Generate Function Polarity Invert
  [0] ? — Time Stamp Generate Function PPM Direction
{0x3D0EC+0x20*i} TS_GENF{i}_LENGTH_REG (i=0..2) — Time Stamp Generate Function Length Value
  [31:0] ?
{0x3D0F0+0x20*i} TS_GENF{i}_PPM_LOW_REG (i=0..2) — Time Stamp Generate Function PPM Low Value
  [31:0] ?
{0x3D0F4+0x20*i} TS_GENF{i}_PPM_HIGH_REG (i=0..2) — Time Stamp Generate Function PPM High Value
  [9:0] ?
{0x3D0F8+0x20*i} TS_GENF{i}_NUDGE_REG (i=0..2) — Time Stamp Generate Function Nudge Value
  [7:0] ?
0x3D200 TS_ESTF_COMP_LOW_REG — Time Stamp ESTF Generate Function Comparison Low Value
  [31:0] ?
0x3D204 TS_ESTF_COMP_HIGH_REG — Time Stamp ESTF Generate Function Comparison high Value
  [31:0] ? — Time Stamp ESTF Generate Function Comparison High Value
0x3D208 TS_ESTF_CONTROL_REG — Time Stamp ESTF Generate Function Control
  [1] ? — Time Stamp ESTF Generate Function Polarity Invert
  [0] ? — Time Stamp ESTF Generate Function PPM Direction
0x3D20C TS_ESTF_LENGTH_REG — Time Stamp ESTF Generate Function Length Value
  [31:0] ?
0x3D210 TS_ESTF_PPM_LOW_REG — Time Stamp ESTF Generate Function PPM Low Value
  [31:0] ?
0x3D214 TS_ESTF_PPM_HIGH_REG — Time Stamp ESTF Generate Function PPM High Value
  [9:0] ?
0x3D218 TS_ESTF_NUDGE_REG — Time Stamp ESTF Generate Function Nudge Value
  [7:0] ?
0x3E000 ALE_MOD_VER ro — The Module and Version Register identifies the module identifier and revision of the ALE_2g32 module.
  [31:16] ? — ALE_2g32 module ID.
  [15:11] ? — RTL Version.
  [10:8] ? — Major Revision.
  [7:6] ? — Custom Revision.
  [5:0] ? — Minor Revision.
0x3E004 ALE_ALE_STATUS ro — The ALE status provides information on the ALE configuration and state. The ~iramdepth is used to determine how IPv6 entries are stored in the table. IPv6 entries are stored in two entries where IPv6 Entry hi is designated by the odd slice index and lo is designated by the even slice index. The slice index is above the ram depth like {SlixeIndex,RamIndex}. So for a 64 deep RAM index of 0x005, the Hi portion of the IPv6 entry is located at 0x005|0x040 and the Lo portion is located at 0x005&(~0x040).
  [31] ? — When set, the unregistered multicast field is a mask versus an index on 12 bit boundary in the ALE table.
  [30] ? — When set, the unregistered multicast field is a mask versus an index on 8 bit boundary in the ALE table.
  [15:8] ? — This is the number of Classifiers the ALE implements divided by 8. A value of 4 indicates 32 policer engines total.
  [7] ? — The number of ALE entries per slice of the table when this is set it indicates the depth is 128 if both ramdepth128 and ramdepth32 are zero the depth is 64.
  [6] ? — The number of ALE entries per slice of the table when this is set it indicates the depth is 32 if both ramdepth128 and ramdepth32 are zero the depth is 64.
  [4:0] ? — This is the number of table entries total divided by 1024. A value of 1 indicates 1024 table entries. A value of 8 indicates 8192 table entries.
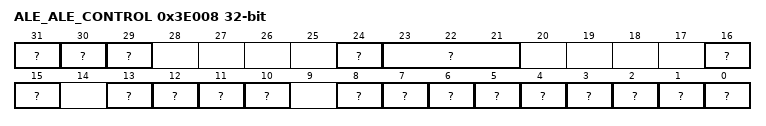
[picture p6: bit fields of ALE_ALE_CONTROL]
0x3E008 ALE_ALE_CONTROL — The ALE Control Register is used to set the ALE modes used for all ports.
  [31] ? — Enable ALE#br# 0 - Drop all packets#br# 1 - Enable ALE packet processing
  [30] ? — Clear ALE address table - Setting this bit causes the ALE hardware to write all table bit values to zero. Software must perform a clear table operation as part of the ALE setup/configuration process. Setting this bit causes all ALE accesses to be held up for 64 clocks while the clear is performed. Access to all ALE registers will be blocked (wait states) until the 64 clocks have completed. This bit cannot be read as one because the read is blocked until the clear table is completed at which time this bit is cleared to zero.
  [29] ? — Age Out Address Table Now - Setting this bit causes the ALE hardware to remove (free up) any ageable table entry that does not have a set touch bit. This bit is cleared when the age out process has completed. This bit may be read. The age out process takes four times the number of table entries clock cycles (4096 cycles for 1K addresses) best case (no ale packet processing during ageout) and sixty five times the number of table entries clock cycles (66560 cycles for 1K addresses) absolute worst case.
  [24] ? — Mirror Destination Port - This field defines the port to which destination traffic destined will be duplicated. That is all traffic that is forwarded to this port will also be mirrored to the ~imirror_top port.
  [23:21] ? — The ~iupd_bw_ctrl field allows for up to 8 times the rate in which adds, updates, touches, writes, and aging updates can occur. At frequencies of 350Mhz, the table update rate should be at it lowest or 5 Million updates per second. When operating the switch core at frequencies or above, the ~iupd_bw_ctrl can be programmed more aggressive. If the ~iupd_bw_ctrl is set but the frequency of the switch subsystem is below the associated value, ALE will drop packets due to insufficient time to complete lookup under high traffic loads.#br# 0 - 350Mhz, 5M#br# 1 - 359Mhz, 11M#br# 2 - 367Mhz, 16M#br# 3 - 375Mhz, 22M#br# 4 - 384Mhz, 28M#br# 5 - 392Mhz, 34M#br# 6 - 400Mhz, 39M#br# 7 - 409Mhz, 45M
  [16] ? — Mirror To Port - This field defines the destination port for the mirror traffic. If the traffic is received or transmitted on the mirror destination port it will not be duplicated. Traffic defined as mirror traffic only may be dropped by the switch due to congestion.
  [15] ? — Update Static Entries - A static Entry is an entry that is not agable. When clear this bit will prevent any static entry (agable bit clear) from being updated due to port change. When set it allows static entries (agable bit clear) to update the source port if required. This bit should normally be '0' for most switch configurations.
  [13] ? — Unknown VLAN No Learn - This field when set will prevent source addresses of unknown VLAN IDs from being automatically added into the look up table if learning is enabled.
  [12] ? — Mirror Match Entry Enable - This field enables the match mirror option. When this bit is set any traffic whose destination, source, VLAN or OUI matches the ~imirror_midx entry index will have that traffic also sent to the ~imirror_top port.
  [11] ? — Mirror Destination Port Enable - This field enables the destination port mirror option. When this bit is set any traffic destined for the ~imirror_dp port will have its transmit traffic also sent to the ~imirror_top port.
  [10] ? — Mirror Source Port Enable - This field enables the source port mirror option. When this bit is set any port with the ~ipX_mirror_sp set in the ALE Port Control registers set will have its received traffic also sent to the ~imirror_top port.
  [8] ? — Unknown unicast packets flood to host#br# 0 - unknown unicast packets are not sent to the host#br# 1 - unknown unicast packets flood to host port as well as other ports
  [7] ? — Learn No VID -#br# 0 - VID is learned with the source address#br# 1 - VID is not learned with the source address (source address is not tied to VID). Determines the entry type.
  [6] ? — Enable VLAN ID = 0 Mode#br# 0 - Process the priority tagged packet with VID = PORT_VLAN[11:0].#br# 1 - Process the priority tagged packet with VID = 0.
  [5] ? — Enable OUI Deny Mode - When set, any packet with a non-matching OUI source address will be dropped to the host unless the packet destination address matches a supervisory destination address table entry. When cleared, any packet source address matching an OUI address table entry will be dropped to the host unless the destination address matches with a supervisory destination address table entry.
  [4] ? — ALE Bypass - When set, packets received on non-host ports are sent to the host. It is expected that packets from the host are directed to the particular port.#br# 0 - no bypass#br# 1 - bypass the ALE
  [3] ? — Rate Limit Transmit mode#br# 0 - Broadcast and multicast rate limit counters are received port based#br# 1 - Broadcast and multicast rate limit counters are transmit port based
  [2] ? — ALE VLAN Aware - Determines how traffic is forwarded using VLAN rules.#br# 0 - Simple switch rules, packets forwarded to all ports for unknown destinations.#br# 1 - VLAN Aware rules, packets forwarded based on VLAN members
  [1] ? — Enable MAC Authorization Mode - Mac authorization mode requires that all table entries be made by the host software. There is no auto learning of addresses in authorization mode and the packet will be dropped if the source address is not found (and the destination address is not a multicast address with the super table entry bit set).#br# 0 - The ALE is not in MAC authorization mode#br# 1 - The ALE is in MAC authorization mode
  [0] ? — Enable Broadcast and Multicast Rate Limit#br# 0 - Broadcast/Multicast rates not limited#br# 1 - Broadcast/Multicast packet reception limited to the port control register rate limit fields.
